# FPB register map
Vendor: Texas Instruments
Peripheral module from a debugger description file (folder UCD3138R032RSM).
Registers are 32-bit, read-only, reset 0x0 unless marked. A register's access mark holds for its fields unless they carry their own. Offsets are as the file gives them; lines under a group give offsets from that group; [hi:lo] are bit positions; {n}, {i} and the like mark numbered series; 'fields as' and 'values as' point back to an identical list; <NAME> marks a mode.

## FPB
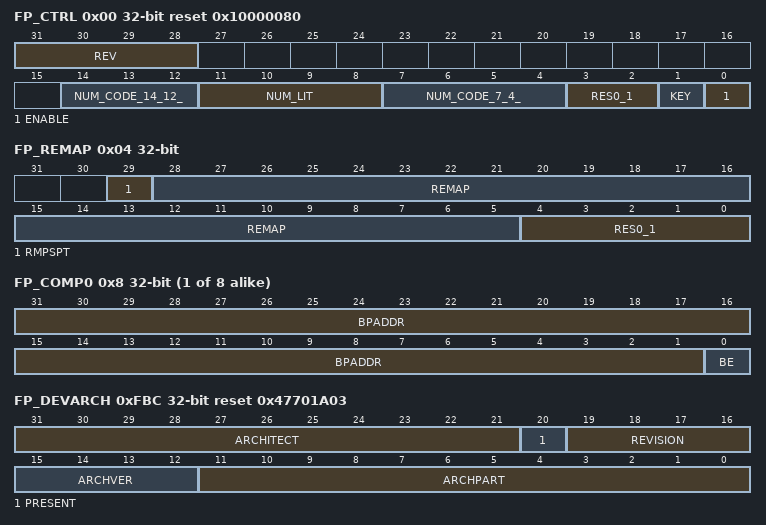
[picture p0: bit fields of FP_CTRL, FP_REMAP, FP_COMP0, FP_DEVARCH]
0x00 FP_CTRL access per field reset 0x10000080 — Provides FPB implementation information, and the global enable for the FPB unit
  [31:28] REV ro — Flash Patch and Breakpoint Unit architecture revision
  [14:12] NUM_CODE_14_12_ ro — Indicates the number of implemented instruction address comparators. Zero indicates no Instruction Address comparators are implemented. The Instruction Address comparators are numbered from 0 to NUM_CODE - 1
  [11:8] NUM_LIT ro — Indicates the number of implemented literal address comparators. The Literal Address comparators are numbered from NUM_CODE to NUM_CODE + NUM_LIT - 1
  [7:4] NUM_CODE_7_4_ ro — Indicates the number of implemented instruction address comparators. Zero indicates no Instruction Address comparators are implemented. The Instruction Address comparators are numbered from 0 to NUM_CODE - 1
  [3:2] RES0_1 ro — Reserved, RES0
  [1] KEY rw — Writes to the FP_CTRL are ignored unless KEY is concurrently written to one
  [0] ENABLE rw — Enables the FPB
0x04 FP_REMAP — Indicates whether the implementation supports Flash Patch remap and, if it does, holds the target address for remap
  [29] RMPSPT — Indicates whether the FPB unit supports the Flash Patch remap function
  [28:5] REMAP — Holds the bits[28:5] of the Flash Patch remap address
  [4:0] RES0_1 — Reserved, RES0
{0x8+4i} FP_COMP{i} rw (i=0..7) — Holds an address for comparison.
  [31:1] BPADDR — Specifies bits[31:1] of the breakpoint instruction address
  [0] BE — Selects between remapping and breakpoint functionality
0xFBC FP_DEVARCH reset 0x47701A03 — Provides CoreSight discovery information for the FPB
  [31:21] ARCHITECT — Defines the architect of the component. Bits [31:28] are the JEP106 continuation code (JEP106 bank ID, minus 1) and bits [27:21] are the JEP106 ID code.
  [20] PRESENT — Defines that the DEVARCH register is present
  [19:16] REVISION — Defines the architecture revision of the component
  [15:12] ARCHVER — Defines the architecture version of the component
  [11:0] ARCHPART — Defines the architecture of the component
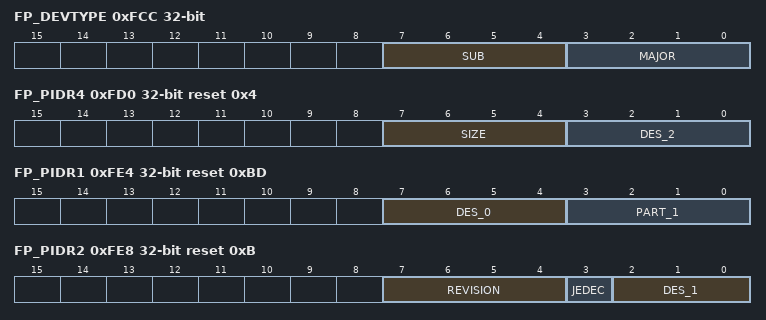
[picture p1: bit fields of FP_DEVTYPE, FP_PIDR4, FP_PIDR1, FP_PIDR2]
0xFCC FP_DEVTYPE — Provides CoreSight discovery information for the FPB
  [7:4] SUB — Component sub-type
  [3:0] MAJOR — Component major type
0xFD0 FP_PIDR4 reset 0x4 — Provides CoreSight discovery information for the FP
  [7:4] SIZE — See CoreSight Architecture Specification
  [3:0] DES_2 — See CoreSight Architecture Specification
{0xFC0+4i} FP_PIDR{i} (i=5..7) — Provides CoreSight discovery information for the FP
0xFE0 FP_PIDR0 reset 0x21 — Provides CoreSight discovery information for the FP
  [7:0] PART_0 — See CoreSight Architecture Specification
0xFE4 FP_PIDR1 reset 0xBD — Provides CoreSight discovery information for the FP
  [7:4] DES_0 — See CoreSight Architecture Specification
  [3:0] PART_1 — See CoreSight Architecture Specification
0xFE8 FP_PIDR2 reset 0xB — Provides CoreSight discovery information for the FP
  [7:4] REVISION — See CoreSight Architecture Specification
  [3] JEDEC — See CoreSight Architecture Specification
  [2:0] DES_1 — See CoreSight Architecture Specification
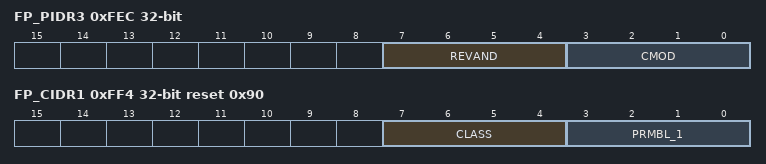
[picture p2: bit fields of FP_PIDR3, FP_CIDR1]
0xFEC FP_PIDR3 — Provides CoreSight discovery information for the FP
  [7:4] REVAND — See CoreSight Architecture Specification
  [3:0] CMOD — See CoreSight Architecture Specification
0xFF0 FP_CIDR0 reset 0xD — Provides CoreSight discovery information for the FP
  [7:0] PRMBL_0 — See CoreSight Architecture Specification
0xFF4 FP_CIDR1 reset 0x90 — Provides CoreSight discovery information for the FP
  [7:4] CLASS — See CoreSight Architecture Specification
  [3:0] PRMBL_1 — See CoreSight Architecture Specification
0xFF8 FP_CIDR2 reset 0x5 — Provides CoreSight discovery information for the FP
  [7:0] PRMBL_2 — See CoreSight Architecture Specification
0xFFC FP_CIDR3 reset 0xB1 — Provides CoreSight discovery information for the FP
  [7:0] PRMBL_3 — See CoreSight Architecture Specification
